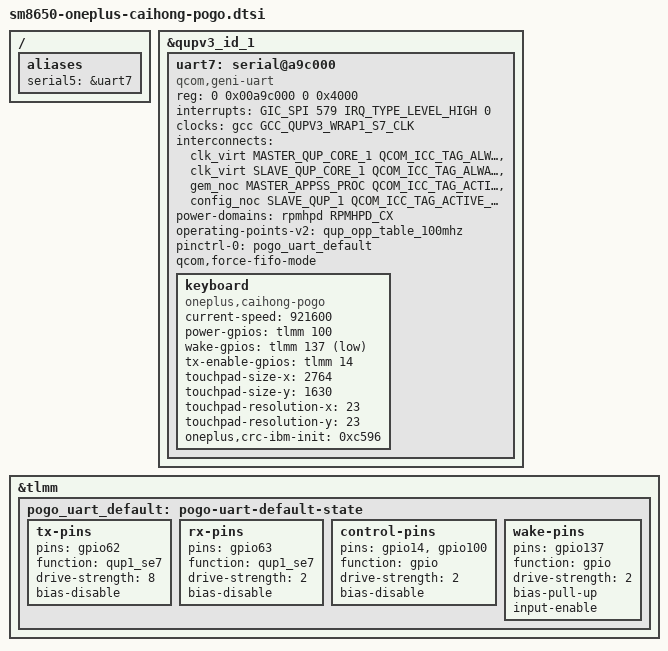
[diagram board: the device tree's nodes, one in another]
// SPDX-License-Identifier: GPL-2.0-only
/* Caihong pogo UART and pin assignment; include from the board DTS. */

/ {
	aliases {
		serial5 = &uart7;
	};
};

&qupv3_id_1 {
	uart7: serial@a9c000 {
		compatible = "qcom,geni-uart";
		reg = <0 0x00a9c000 0 0x4000>;
		interrupts = <GIC_SPI 579 IRQ_TYPE_LEVEL_HIGH 0>;
		clocks = <&gcc GCC_QUPV3_WRAP1_S7_CLK>;
		clock-names = "se";
		interconnects = <&clk_virt MASTER_QUP_CORE_1 QCOM_ICC_TAG_ALWAYS
				 &clk_virt SLAVE_QUP_CORE_1 QCOM_ICC_TAG_ALWAYS>,
				<&gem_noc MASTER_APPSS_PROC QCOM_ICC_TAG_ACTIVE_ONLY
				 &config_noc SLAVE_QUP_1 QCOM_ICC_TAG_ACTIVE_ONLY>;
		interconnect-names = "qup-core", "qup-config";
		power-domains = <&rpmhpd RPMHPD_CX>;
		operating-points-v2 = <&qup_opp_table_100mhz>;
		pinctrl-0 = <&pogo_uart_default>;
		pinctrl-names = "default";
		qcom,force-fifo-mode;
		status = "okay";

		keyboard {
			compatible = "oneplus,caihong-pogo";
			current-speed = <921600>;
			power-gpios = <&tlmm 100 GPIO_ACTIVE_HIGH>;
			wake-gpios = <&tlmm 137 GPIO_ACTIVE_LOW>;
			tx-enable-gpios = <&tlmm 14 GPIO_ACTIVE_HIGH>;
			touchpad-size-x = <2764>;
			touchpad-size-y = <1630>;
			touchpad-resolution-x = <23>;
			touchpad-resolution-y = <23>;
			oneplus,crc-ibm-init = <0xc596>;
		};
	};
};

&tlmm {
	pogo_uart_default: pogo-uart-default-state {
		tx-pins {
			pins = "gpio62";
			function = "qup1_se7";
			drive-strength = <8>;
			bias-disable;
		};

		rx-pins {
			pins = "gpio63";
			function = "qup1_se7";
			drive-strength = <2>;
			bias-disable;
		};

		control-pins {
			pins = "gpio14", "gpio100";
			function = "gpio";
			drive-strength = <2>;
			bias-disable;
		};

		wake-pins {
			pins = "gpio137";
			function = "gpio";
			drive-strength = <2>;
			bias-pull-up;
			input-enable;
		};
	};
};
